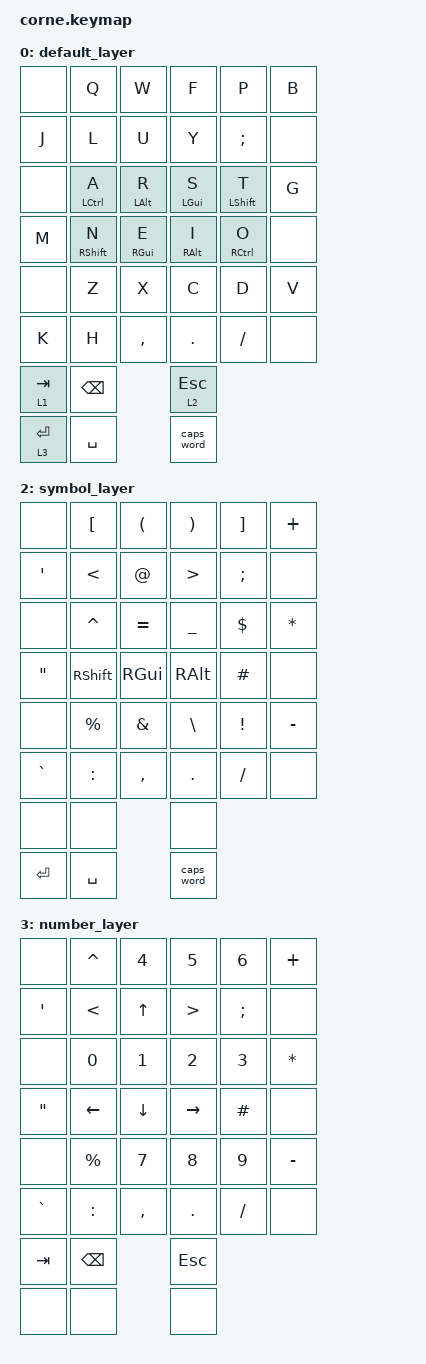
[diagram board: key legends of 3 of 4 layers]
/*
 * Copyright (c) 2020 The ZMK Contributors
 *
 * SPDX-License-Identifier: MIT
 */

#include <behaviors.dtsi>
#include <dt-bindings/zmk/keys.h>
#include <dt-bindings/zmk/bt.h>
#include <dt-bindings/zmk/outputs.h>

/*                              36 KEY MATRIX / LAYOUT MAPPING

  ╭────────────────────┬────────────────────╮ ╭─────────────────────┬─────────────────────╮
  │  0   1   2   3   4 │  5   6   7   8   9 │ │ LT4 LT3 LT2 LT1 LT0 │ RT0 RT1 RT2 RT3 RT4 │
  │ 10  11  12  13  14 │ 15  16  17  18  19 │ │ LM4 LM3 LM2 LM1 LM0 │ RM0 RM1 RM2 RM3 RM4 │
  │ 20  21  22  23  24 │ 25  26  27  28  29 │ │ LB4 LB3 LB2 LB1 LB0 │ RB0 RB1 RB2 RB3 RB4 │
  ╰───────╮ 30  31  32 │ 33  34  35 ╭───────╯ ╰───────╮ LH2 LH1 LH0 │ RH0 RH1 RH2 ╭───────╯
          ╰────────────┴────────────╯                 ╰─────────────┴─────────────╯             */

#pragma once

#define LT0  4  // left-top row
#define LT1  3
#define LT2  2
#define LT3  1
#define LT4  0

#define RT0  5  // right-top row
#define RT1  6
#define RT2  7
#define RT3  8
#define RT4  9

#define LM0 14  // left-middle row
#define LM1 13
#define LM2 12
#define LM3 11
#define LM4 10

#define RM0 15  // right-middle row
#define RM1 16
#define RM2 17
#define RM3 18
#define RM4 19

#define LB0 24  // left-bottom row
#define LB1 23
#define LB2 22
#define LB3 21
#define LB4 20

#define RB0 25  // right-bottom row
#define RB1 26
#define RB2 27
#define RB3 28
#define RB4 29

#define LH0 32  // left thumb keys
#define LH1 31
#define LH2 30

#define RH0 33  // right thumb keys
#define RH1 34
#define RH2 35

// corne key mappings
#define KEYS_L LT0 LT1 LT2 LT3 LT4 LM0 LM1 LM2 LM3 LM4 LB0 LB1 LB2 LB3 LB4
#define KEYS_R RT0 RT1 RT2 RT3 RT4 RM0 RM1 RM2 RM3 RM4 RB0 RB1 RB2 RB3 RB4
#define THUMBS LH2 LH1 LH0 RH0 RH1 RH2

// mod tap combos
#define LT_BLT &lt 1 TAB
#define LT_SYM &lt 2 ESC
#define LT_NUM &lt 3 RET

// constants for hold tap 
#define TAPPING_TERM_MS 200
#define QUICK_TAP_MS 150
#define REQUIRE_PRIOR_IDLE_MS 150

/ {
        behaviors {
                lh_hr_mt: lh_hr_mt {
                        compatible = "zmk,behavior-hold-tap";
                        #binding-cells = <2>;
                        flavor = "balanced";
                        tapping-term-ms = <TAPPING_TERM_MS>;
                        quick-tap-ms = <QUICK_TAP_MS>;
                        require-prior-idle-ms = <REQUIRE_PRIOR_IDLE_MS>;
                        hold-trigger-key-positions = <KEYS_L THUMBS>;
                        hold-trigger-on-release;
                        bindings =  <&kp>, <&kp>;
                };
                rh_hr_mt: rh_hr_mt {
                        compatible = "zmk,behavior-hold-tap";
                        #binding-cells = <2>;
                        flavor = "balanced";
                        tapping-term-ms = <TAPPING_TERM_MS>;
                        quick-tap-ms = <QUICK_TAP_MS>;
                        require-prior-idle-ms = <REQUIRE_PRIOR_IDLE_MS>;
                        hold-trigger-key-positions = <KEYS_R THUMBS>;
                        hold-trigger-on-release;
                        bindings =  <&kp>, <&kp>;
                };
        };

        keymap {
                compatible = "zmk,keymap";

                // default_layer (0)
                // --------------------------------------------------------------------
                // |  Q  |  W  |  F  |  P  |  B  |      |  J  |  L  |  U  |  Y  |  ;  |
                // |  A  |  R  |  S  |  T  |  G  |      |  M  |  N  |  E  |  I  |  O  |
                // |  Z  |  X  |  C  |  D  |  V  |      |  K  |  H  |  ,  |  .  |  /  |
                //             | TAB | BSP | ESC |      | RET | SPC | CPS |

                default_layer {
                        bindings = <
                                &none &kp Q &kp W &kp F &kp P &kp B                                                     // top left
                                &kp J &kp L &kp U &kp Y &kp SEMI &none                                                  // top right
                                &none &lh_hr_mt LCTRL A &lh_hr_mt LALT R &lh_hr_mt LGUI S &lh_hr_mt LSHFT T &kp G       // mid left
                                &kp M &rh_hr_mt RSHFT N &rh_hr_mt RGUI E &rh_hr_mt RALT I &rh_hr_mt RCTRL O &none       // mid right
                                &none &kp Z &kp X &kp C &kp D &kp V                                                     // bot left
                                &kp K &kp H &kp COMMA &kp DOT &kp FSLH &none                                            // bot right
                                LT_BLT &kp BKSP LT_SYM                                                                  // thm left
                                LT_NUM &kp SPACE &caps_word                                                             // thm right
                        >;
                };

                // bt_layer (1)
                // --------------------------------------------------------------------
                // | F1  | F2  | F3  | F4  | F5  |      |  F6 |  F7 |  F8 |  F9 | F10 |
                // | BT1 | BT2 | BT3 | BT4 | BT5 |      | VUP | VMT |     |     |     |
                // | CLR | ALL |     | USB | BLT |      | VDN |     |     |     |     |
                //             |     |     |     |      |     |     |     |

                bt_layer {
                        bindings = <
                                &none &kp F1 &kp F2 &kp F3 &kp F4 &kp F5                                                // top left
                                &kp F6 &kp F7 &kp F8 &kp F9 &kp F10 &none                                               // top right
                                &none &bt BT_SEL 0 &bt BT_SEL 1 &bt BT_SEL 2 &bt BT_SEL 3 &bt BT_SEL 4                  // mid left
                                &kp C_VOL_UP &kp C_MUTE &none &none &none &none &none                                   // mid right
                                &none &bt BT_CLR &bt BT_CLR_ALL &none &out OUT_USB &out OUT_BLE                         // bot left
                                &kp C_VOL_DN &none &none &none &none &none &none                                            // bot right
                                &none &none &none                                                                       // thm left
                                &none &none &none                                                                       // thm right
                        >;
                };

                // symbol_layer (2)
                // --------------------------------------------------------------------
                // |  [  |  (  |  )  |  ]  |  +  |      |  '  |  <  |  @  |  >  |  ;  |
                // |  ^  |  =  |  _  |  $  |  *  |      |  "  | SHT | GUI | ALT |  #  |
                // |  %  |  &  |  \  |  !  |  -  |      |  `  |  :  |  ,  |  .  |  /  |
                //             |     |     |     |      | RET | SPC | CPS |

                symbol_layer {
                        bindings = <
                                &none &kp LBKT &kp LPAR &kp RPAR &kp RBKT &kp PLUS                                      // top left
                                &kp SQT &kp LT &kp AT &kp GT &kp SEMI &none                                             // top right
                                &none &kp CARET &kp EQUAL &kp UNDER &kp DLLR &kp ASTRK                                  // mid left
                                &kp DQT &kp RSHFT &kp RGUI  &kp RALT &kp HASH &none                                     // mid right
                                &none &kp PRCNT &kp AMPS &kp BSLH &kp EXCL &kp MINUS                                    // bot left
                                &kp GRAVE &kp COLON &kp COMMA &kp DOT &kp FSLH &none                                    // bot right
                                &none &none &none                                                                       // thm left
                                &kp RET &kp SPACE &caps_word                                                            // thm right
                        >;
                };

                // number_layer (3)
                // --------------------------------------------------------------------
                // |  ^  |  4  |  5  |  6  |  +  |      |  '  |  <  |  UP |  >  |  ;  |
                // |  0  |  1  |  2  |  3  |  *  |      |  "  | LFT | DWN | RGT |  #  |
                // |  %  |  7  |  8  |  9  |  -  |      |  `  |  :  |  ,  |  .  |  /  |
                //             | TAB | BSP | ESC |      |     |     |     |
                
                number_layer {
                        bindings = <
                                &none &kp CARET &kp N4 &kp N5 &kp N6 &kp PLUS                                           // top left
                                &kp SQT &kp LT &kp UP &kp GT &kp SEMI &none                                             // top right
                                &none &kp N0 &kp N1 &kp N2 &kp N3 &kp ASTRK                                             // mid left
                                &kp DQT &kp LEFT &kp DOWN &kp RIGHT &kp HASH &none                                      // mid right
                                &none &kp PRCNT &kp N7 &kp N8 &kp N9 &kp MINUS                                          // bot left
                                &kp GRAVE &kp COLON &kp COMMA &kp DOT &kp FSLH &none                                    // bot right
                                &kp TAB &kp BKSP &kp ESC                                                                // thm left
                                &none &none &none                                                                       // thm right
                        >;
                };
        };
};
